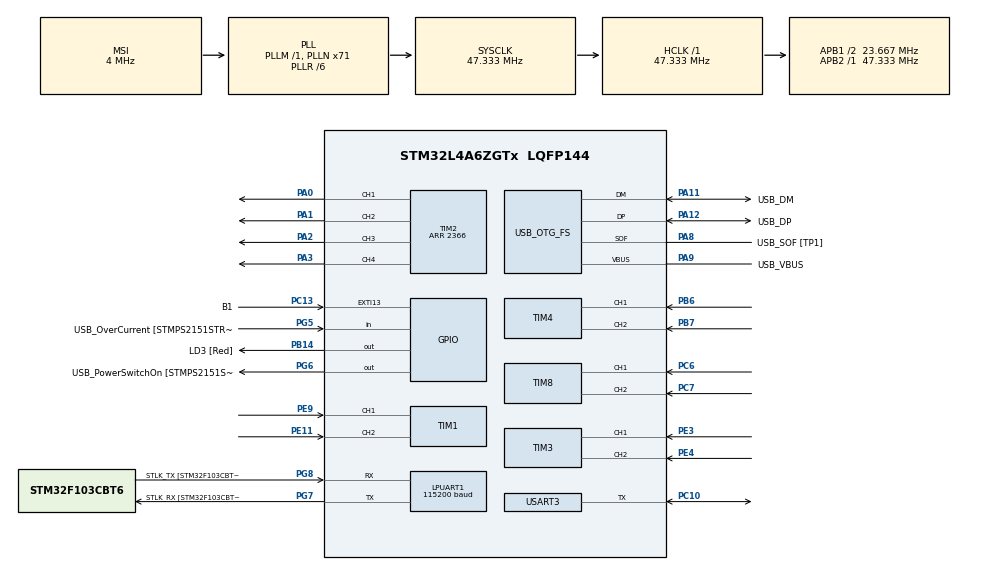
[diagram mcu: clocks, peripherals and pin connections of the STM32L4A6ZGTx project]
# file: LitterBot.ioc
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LPUART1.AutoBaudRateEnableParam=UART_ADVFEATURE_AUTOBAUDRATE_DISABLE
LPUART1.BaudRate=115200
LPUART1.DMADisableonRxErrorParam=UART_ADVFEATURE_DMA_ENABLEONRXERROR
LPUART1.DataInvertParam=UART_ADVFEATURE_DATAINV_DISABLE
LPUART1.MSBFirstParam=UART_ADVFEATURE_MSBFIRST_DISABLE
LPUART1.Mode=UART_MODE_TX_RX
LPUART1.OneBitSampling=UART_ONE_BIT_SAMPLE_DISABLE
LPUART1.OverrunDisableParam=UART_ADVFEATURE_OVERRUN_ENABLE
LPUART1.Parity=UART_PARITY_NONE
LPUART1.RxPinLevelInvertParam=UART_ADVFEATURE_RXINV_DISABLE
LPUART1.StopBits=UART_STOPBITS_1
LPUART1.SwapParam=UART_ADVFEATURE_SWAP_DISABLE
LPUART1.TxPinLevelInvertParam=UART_ADVFEATURE_TXINV_DISABLE
LPUART1.WordLength=UART_WORDLENGTH_9B
Mcu.Family=STM32L4
Mcu.Name=STM32L4A6ZGTx
Mcu.Package=LQFP144
NVIC.PriorityGroup=NVIC_PRIORITYGROUP_4
PA0.Signal=S_TIM2_CH1
PA1.Signal=S_TIM2_CH2
PA10.GPIO_Label=USB_ID
PA10.Signal=USB_OTG_FS_ID
PA11.GPIO_Label=USB_DM
PA11.Mode=Device_Only
PA11.Signal=USB_OTG_FS_DM
PA12.GPIO_Label=USB_DP
PA12.Mode=Device_Only
PA12.Signal=USB_OTG_FS_DP
PA13\ (JTMS/SWDIO).GPIO_Label=TMS
PA13\ (JTMS/SWDIO).Mode=Trace_Asynchronous_SW
PA13\ (JTMS/SWDIO).Signal=SYS_JTMS-SWDIO
PA14\ (JTCK/SWCLK).GPIO_Label=TCK
PA14\ (JTCK/SWCLK).Mode=Trace_Asynchronous_SW
PA14\ (JTCK/SWCLK).Signal=SYS_JTCK-SWCLK
PA2.Signal=S_TIM2_CH3
PA3.Signal=S_TIM2_CH4
PA8.GPIO_Label=USB_SOF [TP1]
PA8.Mode=Activate_SOF_FS
PA8.Signal=USB_OTG_FS_SOF
PA9.GPIO_Label=USB_VBUS
PA9.Mode=Activate_VBUS
PA9.Signal=USB_OTG_FS_VBUS
PB14.GPIO_Label=LD3 [Red]
PB14.Signal=GPIO_Output
PB3\ (JTDO/TRACESWO).GPIO_Label=SWO
PB3\ (JTDO/TRACESWO).Mode=Trace_Asynchronous_SW
PB3\ (JTDO/TRACESWO).Signal=SYS_JTDO-SWO
PB6.Signal=S_TIM4_CH1
PB7.Signal=S_TIM4_CH2
PC10.Mode=Half_duplex(single_wire_mode)
PC10.Signal=USART3_TX
PC13.GPIO_Label=B1
PC13.Signal=GPXTI13
PC14-OSC32_IN\ (PC14).Mode=LSE-External-Oscillator
PC14-OSC32_IN\ (PC14).Signal=RCC_OSC32_IN
PC15-OSC32_OUT\ (PC15).Mode=LSE-External-Oscillator
PC15-OSC32_OUT\ (PC15).Signal=RCC_OSC32_OUT
PC6.Signal=S_TIM8_CH1
PC7.Signal=S_TIM8_CH2
PE11.Signal=S_TIM1_CH2
PE3.Signal=S_TIM3_CH1
PE4.Signal=S_TIM3_CH2
PE9.Signal=S_TIM1_CH1
PG5.GPIO_Label=USB_OverCurrent [STMPS2151STR_FAULT]
PG5.Signal=GPIO_Input
PG6.GPIO_Label=USB_PowerSwitchOn [STMPS2151STR_EN]
PG6.Signal=GPIO_Output
PG7.GPIO_Label=STLK_RX [STM32F103CBT6_PA3]
PG7.Mode=Asynchronous
PG7.Signal=LPUART1_TX
PG8.GPIO_Label=STLK_TX [STM32F103CBT6_PA2]
PG8.Mode=Asynchronous
PG8.Signal=LPUART1_RX
PH1-OSC_OUT\ (PH1).Signal=RCC_OSC_OUT
ProjectManager.HeapSize=0x200
ProjectManager.StackSize=0x400
ProjectManager.TargetToolchain=STM32CubeIDE
RCC.ADCFreq_Value=48000000
RCC.AHBFreq_Value=47333333.333333336
RCC.APB1CLKDivider=RCC_HCLK_DIV2
RCC.APB1Freq_Value=23666666.666666668
RCC.APB1TimFreq_Value=47333333.333333336
RCC.APB2Freq_Value=47333333.333333336
RCC.APB2TimFreq_Value=47333333.333333336
RCC.CortexFreq_Value=47333333.333333336
RCC.FLatency=FLASH_LATENCY_2
RCC.HCLKFreq_Value=47333333.333333336
RCC.HSE_VALUE=8000000
RCC.HSI48_VALUE=48000000
RCC.HSI_VALUE=16000000
RCC.MSI_VALUE=4000000
RCC.PLLN=71
RCC.PLLR=RCC_PLLR_DIV6
RCC.PLLSAI1N=24
RCC.SYSCLKFreq_VALUE=47333333.333333336
RCC.SYSCLKSource=RCC_SYSCLKSOURCE_PLLCLK
RCC.USBFreq_Value=48000000
RCC.VCOOutputFreq_Value=284000000
SH.S_TIM1_CH1.0=TIM1_CH1,Encoder_Interface
SH.S_TIM1_CH2.0=TIM1_CH2,Encoder_Interface
SH.S_TIM2_CH1.0=TIM2_CH1,PWM Generation1 CH1
SH.S_TIM2_CH2.0=TIM2_CH2,PWM Generation2 CH2
SH.S_TIM2_CH3.0=TIM2_CH3,PWM Generation3 CH3
SH.S_TIM2_CH4.0=TIM2_CH4,PWM Generation4 CH4
SH.S_TIM3_CH1.0=TIM3_CH1,Encoder_Interface
SH.S_TIM3_CH2.0=TIM3_CH2,Encoder_Interface
SH.S_TIM4_CH1.0=TIM4_CH1,Encoder_Interface
SH.S_TIM4_CH2.0=TIM4_CH2,Encoder_Interface
SH.S_TIM8_CH1.0=TIM8_CH1,Encoder_Interface
SH.S_TIM8_CH2.0=TIM8_CH2,Encoder_Interface
TIM1.EncoderMode=TIM_ENCODERMODE_TI12
TIM2.Channel-PWM\ Generation1\ CH1=TIM_CHANNEL_1
TIM2.Channel-PWM\ Generation2\ CH2=TIM_CHANNEL_2
TIM2.Channel-PWM\ Generation3\ CH3=TIM_CHANNEL_3
TIM2.Channel-PWM\ Generation4\ CH4=TIM_CHANNEL_4
TIM2.Period=2366
TIM3.EncoderMode=TIM_ENCODERMODE_TI12
TIM4.EncoderMode=TIM_ENCODERMODE_TI12
TIM8.EncoderMode=TIM_ENCODERMODE_TI12
USART3.AutoBaudRateEnableParam=UART_ADVFEATURE_AUTOBAUDRATE_DISABLE
USART3.BaudRate=1000000
USART3.VirtualMode-Half_duplex(single_wire_mode)=VM_ASYNC
USB_OTG_FS.Sof_enable=ENABLE
USB_OTG_FS.VirtualMode=Device_Only
USB_OTG_FS.battery_charging_enable=ENABLE
USB_OTG_FS.low_power_enable=DISABLE
USB_OTG_FS.lpm_enable=DISABLE
USB_OTG_FS.use_dedicated_ep1=DISABLE
USB_OTG_FS.vbus_sensing_enable=ENABLE
VP_TIM2_VS_ClockSourceINT.Mode=Internal
board=NUCLEO-L4A6ZG

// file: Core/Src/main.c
/* USER CODE BEGIN Header */
/**
  ******************************************************************************
  * @file           : main.c
  * @brief          : Main program body
  ******************************************************************************
  * @attention
  *f
  * Copyright (c) 2026 STMicroelectronics.
  * All rights reserved.
  *
  * This software is licensed under terms that can be found in the LICENSE file
  * in the root directory of this software component.
  * If no LICENSE file comes with this software, it is provided AS-IS.
  *
  ******************************************************************************
  */
/* USER CODE END Header */
#include "main.h"

/* USEIncludes */

  // #include "servo_test.h"
  // #include "dc_motor_test.h"
  // #include "stepper_test.h"
  // #include "combined_test.h"
  #include "encoder.h"
  #include "odometry.h"
  #include "uart_cmd.h"
  #include "calibration_store.h"
  // #include "encoder_test.h"

UART_HandleTypeDef hlpuart1;
UART_HandleTypeDef huart3;

TIM_HandleTypeDef htim1;
TIM_HandleTypeDef htim2;
TIM_HandleTypeDef htim3;
TIM_HandleTypeDef htim4;
TIM_HandleTypeDef htim8;

PCD_HandleTypeDef hpcd_USB_OTG_FS;

/* USER CODE BEGIN PV */
static uint8_t rx_byte;
/* USER CODE END PV */

void SystemClock_Config(void);
static void MX_GPIO_Init(void);
static void MX_LPUART1_UART_Init(void);
static void MX_USB_OTG_FS_PCD_Init(void);
static void MX_TIM2_Init(void);
static void MX_USART3_UART_Init(void);
static void MX_TIM1_Init(void);
static void MX_TIM3_Init(void);
static void MX_TIM4_Init(void);
static void MX_TIM8_Init(void);

int main(void)
{

  /* MCU Configuration--------------------------------------------------------*/

  /* Reset of all peripherals, Initializes the Flash interface and the Systick. */
  HAL_Init();

  /* Configure the system clock */
  SystemClock_Config();

  /* Initialize all configured peripherals */
  MX_GPIO_Init();
  MX_LPUART1_UART_Init();
  MX_USB_OTG_FS_PCD_Init();
  MX_TIM2_Init();
  MX_USART3_UART_Init();
  MX_TIM1_Init();
  MX_TIM3_Init();
  MX_TIM4_Init();
  MX_TIM8_Init();
  /* USER CODE BEGIN 2 */
  // ServoTest_Init(&huart3);
  // DCMotorTest_Init();
  // StepperTest_Init();
  // CombinedTest_Init(&huart3);

  /* Match LitterBot_v2_workspace_1.18.0: 300 ms settle after USART3 init
   * before the first servo packet. v2's working main() has this exact
   * delay between MX_USART3_UART_Init() and the first hx65_write_pos(). */
  HAL_Delay(300);

  Encoder_Init();
  Odometry_Init();
  CalStore_Init();
  UartCmd_Init(&hlpuart1);
  HAL_UART_Receive_IT(&hlpuart1, &rx_byte, 1);

  // --- Encoder test standalone (B1 button only, no teleop) ---
  // EncoderTest_Init(&hlpuart1);
  /* USER CODE END 2 */

  /* Infinite loop */
  while (1)
  {

    /* USER CODE BEGIN 3 */
    // ServoTest_Poll();
    // DCMotorTest_Poll();
    // StepperTest_Poll();
    // CombinedTest_Poll();

    // --- UART teleop + encoder telemetry (ROS2 mode) ---
    Encoder_Update();
    Odometry_Update();
    UartCmd_Task(HAL_GetTick());
    UartCmd_TelemetryTask(HAL_GetTick());

    /* Heartbeat: LD3 (PB14) blinks at ~1 Hz to confirm firmware is alive */
    static uint32_t last_hb = 0;
    uint32_t now = HAL_GetTick();
    if (now - last_hb >= 500) {
        HAL_GPIO_TogglePin(LD3_GPIO_Port, LD3_Pin);
        last_hb = now;
    }
  }
  /* USER CODE END 3 */
}

void SystemClock_Config(void)
{
  RCC_OscInitTypeDef RCC_OscInitStruct = {0};
  RCC_ClkInitTypeDef RCC_ClkInitStruct = {0};

  /** Configure the main internal regulator output voltage
  */
  if (HAL_PWREx_ControlVoltageScaling(PWR_REGULATOR_VOLTAGE_SCALE1) != HAL_OK)
  {
    Error_Handler();
  }

  /** Configure LSE Drive Capability
  */
  HAL_PWR_EnableBkUpAccess();
  __HAL_RCC_LSEDRIVE_CONFIG(RCC_LSEDRIVE_LOW);

  /** Initializes the RCC Oscillators according to the specified parameters
  * in the RCC_OscInitTypeDef structure.
  */
  RCC_OscInitStruct.OscillatorType = RCC_OSCILLATORTYPE_LSE|RCC_OSCILLATORTYPE_MSI;
  RCC_OscInitStruct.LSEState = RCC_LSE_ON;
  RCC_OscInitStruct.MSIState = RCC_MSI_ON;
  RCC_OscInitStruct.MSICalibrationValue = 0;
  RCC_OscInitStruct.MSIClockRange = RCC_MSIRANGE_6;
  RCC_OscInitStruct.PLL.PLLState = RCC_PLL_ON;
  RCC_OscInitStruct.PLL.PLLSource = RCC_PLLSOURCE_MSI;
  RCC_OscInitStruct.PLL.PLLM = 1;
  RCC_OscInitStruct.PLL.PLLN = 71;
  RCC_OscInitStruct.PLL.PLLP = RCC_PLLP_DIV2;
  RCC_OscInitStruct.PLL.PLLQ = RCC_PLLQ_DIV2;
  RCC_OscInitStruct.PLL.PLLR = RCC_PLLR_DIV6;
  if (HAL_RCC_OscConfig(&RCC_OscInitStruct) != HAL_OK)
  {
    Error_Handler();
  }

  /** Initializes the CPU, AHB and APB buses clocks
  */
  RCC_ClkInitStruct.ClockType = RCC_CLOCKTYPE_HCLK|RCC_CLOCKTYPE_SYSCLK
                              |RCC_CLOCKTYPE_PCLK1|RCC_CLOCKTYPE_PCLK2;
  RCC_ClkInitStruct.SYSCLKSource = RCC_SYSCLKSOURCE_PLLCLK;
  RCC_ClkInitStruct.AHBCLKDivider = RCC_SYSCLK_DIV1;
  RCC_ClkInitStruct.APB1CLKDivider = RCC_HCLK_DIV2;
  RCC_ClkInitStruct.APB2CLKDivider = RCC_HCLK_DIV1;

  if (HAL_RCC_ClockConfig(&RCC_ClkInitStruct, FLASH_LATENCY_2) != HAL_OK)
  {
    Error_Handler();
  }

  /** Enable MSI Auto calibration
  */
  HAL_RCCEx_EnableMSIPLLMode();
}

static void MX_LPUART1_UART_Init(void)
{

  hlpuart1.Instance = LPUART1;
  hlpuart1.Init.BaudRate = 115200;
  hlpuart1.Init.WordLength = UART_WORDLENGTH_8B;
  hlpuart1.Init.StopBits = UART_STOPBITS_1;
  hlpuart1.Init.Parity = UART_PARITY_NONE;
  hlpuart1.Init.Mode = UART_MODE_TX_RX;
  hlpuart1.Init.HwFlowCtl = UART_HWCONTROL_NONE;
  hlpuart1.Init.OneBitSampling = UART_ONE_BIT_SAMPLE_DISABLE;
  hlpuart1.AdvancedInit.AdvFeatureInit = UART_ADVFEATURE_NO_INIT;
  if (HAL_UART_Init(&hlpuart1) != HAL_OK)
  {
    Error_Handler();
  }

}

static void MX_USART3_UART_Init(void)
{

  huart3.Instance = USART3;
  huart3.Init.BaudRate = 1000000;
  huart3.Init.WordLength = UART_WORDLENGTH_8B;
  huart3.Init.StopBits = UART_STOPBITS_1;
  huart3.Init.Parity = UART_PARITY_NONE;
  huart3.Init.Mode = UART_MODE_TX_RX;
  huart3.Init.HwFlowCtl = UART_HWCONTROL_NONE;
  huart3.Init.OverSampling = UART_OVERSAMPLING_16;
  huart3.Init.OneBitSampling = UART_ONE_BIT_SAMPLE_DISABLE;
  huart3.AdvancedInit.AdvFeatureInit = UART_ADVFEATURE_NO_INIT;
  if (HAL_HalfDuplex_Init(&huart3) != HAL_OK)
  {
    Error_Handler();
  }

}

static void MX_TIM1_Init(void)
{

  TIM_Encoder_InitTypeDef sConfig = {0};
  TIM_MasterConfigTypeDef sMasterConfig = {0};

  htim1.Instance = TIM1;
  htim1.Init.Prescaler = 0;
  htim1.Init.CounterMode = TIM_COUNTERMODE_UP;
  htim1.Init.Period = 65535;
  htim1.Init.ClockDivision = TIM_CLOCKDIVISION_DIV1;
  htim1.Init.RepetitionCounter = 0;
  htim1.Init.AutoReloadPreload = TIM_AUTORELOAD_PRELOAD_DISABLE;
  sConfig.EncoderMode = TIM_ENCODERMODE_TI12;
  sConfig.IC1Polarity = TIM_ICPOLARITY_RISING;
  sConfig.IC1Selection = TIM_ICSELECTION_DIRECTTI;
  sConfig.IC1Prescaler = TIM_ICPSC_DIV1;
  sConfig.IC1Filter = 0;
  sConfig.IC2Polarity = TIM_ICPOLARITY_RISING;
  sConfig.IC2Selection = TIM_ICSELECTION_DIRECTTI;
  sConfig.IC2Prescaler = TIM_ICPSC_DIV1;
  sConfig.IC2Filter = 0;
  if (HAL_TIM_Encoder_Init(&htim1, &sConfig) != HAL_OK)
  {
    Error_Handler();
  }
  sMasterConfig.MasterOutputTrigger = TIM_TRGO_RESET;
  sMasterConfig.MasterOutputTrigger2 = TIM_TRGO2_RESET;
  sMasterConfig.MasterSlaveMode = TIM_MASTERSLAVEMODE_DISABLE;
  if (HAL_TIMEx_MasterConfigSynchronization(&htim1, &sMasterConfig) != HAL_OK)
  {
    Error_Handler();
  }

}

static void MX_TIM2_Init(void)
{

  TIM_ClockConfigTypeDef sClockSourceConfig = {0};
  TIM_MasterConfigTypeDef sMasterConfig = {0};
  TIM_OC_InitTypeDef sConfigOC = {0};

  htim2.Instance = TIM2;
  htim2.Init.Prescaler = 0;
  htim2.Init.CounterMode = TIM_COUNTERMODE_UP;
  htim2.Init.Period = 2366;
  htim2.Init.ClockDivision = TIM_CLOCKDIVISION_DIV1;
  htim2.Init.AutoReloadPreload = TIM_AUTORELOAD_PRELOAD_DISABLE;
  if (HAL_TIM_Base_Init(&htim2) != HAL_OK)
  {
    Error_Handler();
  }
  sClockSourceConfig.ClockSource = TIM_CLOCKSOURCE_INTERNAL;
  if (HAL_TIM_ConfigClockSource(&htim2, &sClockSourceConfig) != HAL_OK)
  {
    Error_Handler();
  }
  if (HAL_TIM_PWM_Init(&htim2) != HAL_OK)
  {
    Error_Handler();
  }
  sMasterConfig.MasterOutputTrigger = TIM_TRGO_RESET;
  sMasterConfig.MasterSlaveMode = TIM_MASTERSLAVEMODE_DISABLE;
  if (HAL_TIMEx_MasterConfigSynchronization(&htim2, &sMasterConfig) != HAL_OK)
  {
    Error_Handler();
  }
  sConfigOC.OCMode = TIM_OCMODE_PWM1;
  sConfigOC.Pulse = 0;
  sConfigOC.OCPolarity = TIM_OCPOLARITY_HIGH;
  sConfigOC.OCFastMode = TIM_OCFAST_DISABLE;
  if (HAL_TIM_PWM_ConfigChannel(&htim2, &sConfigOC, TIM_CHANNEL_1) != HAL_OK)
  {
    Error_Handler();
  }
  if (HAL_TIM_PWM_ConfigChannel(&htim2, &sConfigOC, TIM_CHANNEL_2) != HAL_OK)
  {
    Error_Handler();
  }
  if (HAL_TIM_PWM_ConfigChannel(&htim2, &sConfigOC, TIM_CHANNEL_3) != HAL_OK)
  {
    Error_Handler();
  }
  if (HAL_TIM_PWM_ConfigChannel(&htim2, &sConfigOC, TIM_CHANNEL_4) != HAL_OK)
  {
    Error_Handler();
  }
  HAL_TIM_MspPostInit(&htim2);

}

static void MX_TIM3_Init(void)
{

  TIM_Encoder_InitTypeDef sConfig = {0};
  TIM_MasterConfigTypeDef sMasterConfig = {0};

  htim3.Instance = TIM3;
  htim3.Init.Prescaler = 0;
  htim3.Init.CounterMode = TIM_COUNTERMODE_UP;
  htim3.Init.Period = 65535;
  htim3.Init.ClockDivision = TIM_CLOCKDIVISION_DIV1;
  htim3.Init.AutoReloadPreload = TIM_AUTORELOAD_PRELOAD_DISABLE;
  sConfig.EncoderMode = TIM_ENCODERMODE_TI12;
  sConfig.IC1Polarity = TIM_ICPOLARITY_RISING;
  sConfig.IC1Selection = TIM_ICSELECTION_DIRECTTI;
  sConfig.IC1Prescaler = TIM_ICPSC_DIV1;
  sConfig.IC1Filter = 0;
  sConfig.IC2Polarity = TIM_ICPOLARITY_RISING;
  sConfig.IC2Selection = TIM_ICSELECTION_DIRECTTI;
  sConfig.IC2Prescaler = TIM_ICPSC_DIV1;
  sConfig.IC2Filter = 0;
  if (HAL_TIM_Encoder_Init(&htim3, &sConfig) != HAL_OK)
  {
    Error_Handler();
  }
  sMasterConfig.MasterOutputTrigger = TIM_TRGO_RESET;
  sMasterConfig.MasterSlaveMode = TIM_MASTERSLAVEMODE_DISABLE;
  if (HAL_TIMEx_MasterConfigSynchronization(&htim3, &sMasterConfig) != HAL_OK)
  {
    Error_Handler();
  }

}

static void MX_TIM4_Init(void)
{

  TIM_Encoder_InitTypeDef sConfig = {0};
  TIM_MasterConfigTypeDef sMasterConfig = {0};

  htim4.Instance = TIM4;
  htim4.Init.Prescaler = 0;
  htim4.Init.CounterMode = TIM_COUNTERMODE_UP;
  htim4.Init.Period = 65535;
  htim4.Init.ClockDivision = TIM_CLOCKDIVISION_DIV1;
  htim4.Init.AutoReloadPreload = TIM_AUTORELOAD_PRELOAD_DISABLE;
  sConfig.EncoderMode = TIM_ENCODERMODE_TI12;
  sConfig.IC1Polarity = TIM_ICPOLARITY_RISING;
  sConfig.IC1Selection = TIM_ICSELECTION_DIRECTTI;
  sConfig.IC1Prescaler = TIM_ICPSC_DIV1;
  sConfig.IC1Filter = 0;
  sConfig.IC2Polarity = TIM_ICPOLARITY_RISING;
  sConfig.IC2Selection = TIM_ICSELECTION_DIRECTTI;
  sConfig.IC2Prescaler = TIM_ICPSC_DIV1;
  sConfig.IC2Filter = 0;
  if (HAL_TIM_Encoder_Init(&htim4, &sConfig) != HAL_OK)
  {
    Error_Handler();
  }
  sMasterConfig.MasterOutputTrigger = TIM_TRGO_RESET;
  sMasterConfig.MasterSlaveMode = TIM_MASTERSLAVEMODE_DISABLE;
  if (HAL_TIMEx_MasterConfigSynchronization(&htim4, &sMasterConfig) != HAL_OK)
  {
    Error_Handler();
  }

}

static void MX_TIM8_Init(void)
{

  TIM_Encoder_InitTypeDef sConfig = {0};
  TIM_MasterConfigTypeDef sMasterConfig = {0};

  htim8.Instance = TIM8;
  htim8.Init.Prescaler = 0;
  htim8.Init.CounterMode = TIM_COUNTERMODE_UP;
  htim8.Init.Period = 65535;
  htim8.Init.ClockDivision = TIM_CLOCKDIVISION_DIV1;
  htim8.Init.RepetitionCounter = 0;
  htim8.Init.AutoReloadPreload = TIM_AUTORELOAD_PRELOAD_DISABLE;
  sConfig.EncoderMode = TIM_ENCODERMODE_TI12;
  sConfig.IC1Polarity = TIM_ICPOLARITY_RISING;
  sConfig.IC1Selection = TIM_ICSELECTION_DIRECTTI;
  sConfig.IC1Prescaler = TIM_ICPSC_DIV1;
  sConfig.IC1Filter = 0;
  sConfig.IC2Polarity = TIM_ICPOLARITY_RISING;
  sConfig.IC2Selection = TIM_ICSELECTION_DIRECTTI;
  sConfig.IC2Prescaler = TIM_ICPSC_DIV1;
  sConfig.IC2Filter = 0;
  if (HAL_TIM_Encoder_Init(&htim8, &sConfig) != HAL_OK)
  {
    Error_Handler();
  }
  sMasterConfig.MasterOutputTrigger = TIM_TRGO_RESET;
  sMasterConfig.MasterOutputTrigger2 = TIM_TRGO2_RESET;
  sMasterConfig.MasterSlaveMode = TIM_MASTERSLAVEMODE_DISABLE;
  if (HAL_TIMEx_MasterConfigSynchronization(&htim8, &sMasterConfig) != HAL_OK)
  {
    Error_Handler();
  }

}

static void MX_USB_OTG_FS_PCD_Init(void)
{

  hpcd_USB_OTG_FS.Instance = USB_OTG_FS;
  hpcd_USB_OTG_FS.Init.dev_endpoints = 6;
  hpcd_USB_OTG_FS.Init.speed = PCD_SPEED_FULL;
  hpcd_USB_OTG_FS.Init.phy_itface = PCD_PHY_EMBEDDED;
  hpcd_USB_OTG_FS.Init.Sof_enable = ENABLE;
  hpcd_USB_OTG_FS.Init.low_power_enable = DISABLE;
  hpcd_USB_OTG_FS.Init.lpm_enable = DISABLE;
  hpcd_USB_OTG_FS.Init.battery_charging_enable = ENABLE;
  hpcd_USB_OTG_FS.Init.use_dedicated_ep1 = DISABLE;
  hpcd_USB_OTG_FS.Init.vbus_sensing_enable = ENABLE;
  if (HAL_PCD_Init(&hpcd_USB_OTG_FS) != HAL_OK)
  {
    Error_Handler();
  }

}

static void MX_GPIO_Init(void)
{
  GPIO_InitTypeDef GPIO_InitStruct = {0};

  /* GPIO Ports Clock Enable */
  __HAL_RCC_GPIOE_CLK_ENABLE();
  __HAL_RCC_GPIOC_CLK_ENABLE();
  __HAL_RCC_GPIOH_CLK_ENABLE();
  __HAL_RCC_GPIOA_CLK_ENABLE();
  __HAL_RCC_GPIOB_CLK_ENABLE();
  __HAL_RCC_GPIOD_CLK_ENABLE();
  __HAL_RCC_GPIOG_CLK_ENABLE();
  HAL_PWREx_EnableVddIO2();

  /*Configure GPIO pin Output Level */
  HAL_GPIO_WritePin(GPIOB, LD3_Pin|LD2_Pin, GPIO_PIN_RESET);

  /*Configure GPIO pin Output Level */
  HAL_GPIO_WritePin(USB_PowerSwitchOn_GPIO_Port, USB_PowerSwitchOn_Pin, GPIO_PIN_RESET);

  /*Configure GPIO pin : B1_Pin */
  GPIO_InitStruct.Pin = B1_Pin;
  GPIO_InitStruct.Mode = GPIO_MODE_INPUT;  /* Polled only — no EXTI needed */
  GPIO_InitStruct.Pull = GPIO_PULLUP;      /* Pull-up: pin HIGH = not pressed */
  HAL_GPIO_Init(B1_GPIO_Port, &GPIO_InitStruct);

  /*Configure GPIO pins : LD3_Pin LD2_Pin */
  GPIO_InitStruct.Pin = LD3_Pin|LD2_Pin;
  GPIO_InitStruct.Mode = GPIO_MODE_OUTPUT_PP;
  GPIO_InitStruct.Pull = GPIO_NOPULL;
  GPIO_InitStruct.Speed = GPIO_SPEED_FREQ_LOW;
  HAL_GPIO_Init(GPIOB, &GPIO_InitStruct);

  /*Configure GPIO pin : USB_OverCurrent_Pin */
  GPIO_InitStruct.Pin = USB_OverCurrent_Pin;
  GPIO_InitStruct.Mode = GPIO_MODE_INPUT;
  GPIO_InitStruct.Pull = GPIO_NOPULL;
  HAL_GPIO_Init(USB_OverCurrent_GPIO_Port, &GPIO_InitStruct);

  /*Configure GPIO pin : USB_PowerSwitchOn_Pin */
  GPIO_InitStruct.Pin = USB_PowerSwitchOn_Pin;
  GPIO_InitStruct.Mode = GPIO_MODE_OUTPUT_PP;
  GPIO_InitStruct.Pull = GPIO_NOPULL;
  GPIO_InitStruct.Speed = GPIO_SPEED_FREQ_LOW;
  HAL_GPIO_Init(USB_PowerSwitchOn_GPIO_Port, &GPIO_InitStruct);

}

/* USER CODE BEGIN 4 */

void HAL_UART_RxCpltCallback(UART_HandleTypeDef *huart) {
  if (huart->Instance == LPUART1) {
    UartCmd_OnRxByte(rx_byte);
    HAL_UART_Receive_IT(&hlpuart1, &rx_byte, 1);
  }
}

void HAL_UART_ErrorCallback(UART_HandleTypeDef *huart) {
  /* Re-arm the interrupt after any error (framing, overrun, noise).
   * Clear sticky error flags first — overrun (ORE) in particular will
   * immediately re-trigger the error if left set, causing an interrupt storm. */
  if (huart->Instance == LPUART1) {
    __HAL_UART_CLEAR_FLAG(huart, UART_CLEAR_OREF | UART_CLEAR_NEF |
                                  UART_CLEAR_PEF  | UART_CLEAR_FEF);
    __HAL_UART_FLUSH_DRREGISTER(huart);
    HAL_UART_Receive_IT(&hlpuart1, &rx_byte, 1);
  }
}

/* USER CODE END 4 */

void Error_Handler(void)
{
  __disable_irq();
  while (1)
  {
  }
}
